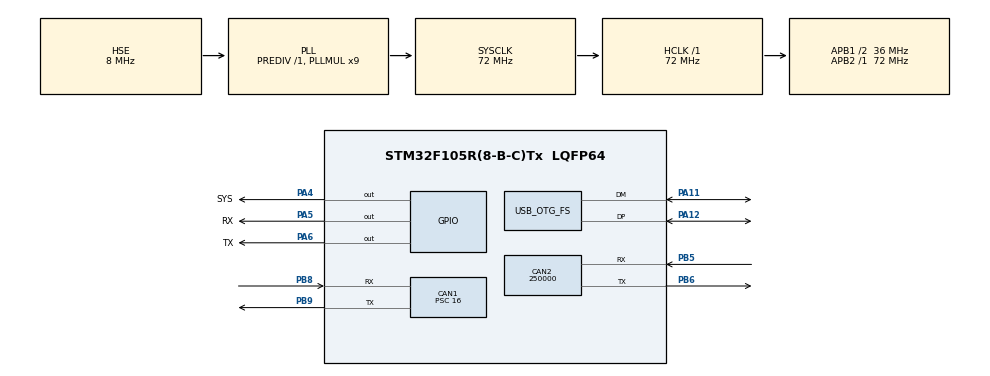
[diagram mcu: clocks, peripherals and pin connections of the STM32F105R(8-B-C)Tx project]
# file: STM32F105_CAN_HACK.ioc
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CAN1.BS1=CAN_BS1_4TQ
CAN1.BS2=CAN_BS2_4TQ
CAN1.CalculateBaudRate=250000
CAN1.CalculateTimeBit=4000
CAN1.CalculateTimeQuantum=444.44444444444446
CAN1.Prescaler=16
CAN2.BS1=CAN_BS1_4TQ
CAN2.BS2=CAN_BS2_4TQ
CAN2.CalculateBaudRate=250000
CAN2.CalculateTimeBit=4000
CAN2.CalculateTimeQuantum=444.44444444444446
Mcu.Family=STM32F1
Mcu.Name=STM32F105R(8-B-C)Tx
Mcu.Package=LQFP64
NVIC.OTG_FS_IRQn=true\:0\:0\:false\:false\:true\:false\:true\:true
NVIC.PriorityGroup=NVIC_PRIORITYGROUP_4
PA11.Mode=Device_Only
PA11.Signal=USB_OTG_FS_DM
PA12.Mode=Device_Only
PA12.Signal=USB_OTG_FS_DP
PA13.Mode=Serial_Wire
PA13.Signal=SYS_JTMS-SWDIO
PA14.Mode=Serial_Wire
PA14.Signal=SYS_JTCK-SWCLK
PA4.GPIO_Label=SYS
PA4.Signal=GPIO_Output
PA5.GPIO_Label=RX
PA5.Signal=GPIO_Output
PA6.GPIO_Label=TX
PA6.Signal=GPIO_Output
PB5.Mode=CAN_Activate
PB5.Signal=CAN2_RX
PB6.Mode=CAN_Activate
PB6.Signal=CAN2_TX
PB8.Mode=CAN_Activate
PB8.Signal=CAN1_RX
PB9.Mode=CAN_Activate
PB9.Signal=CAN1_TX
PD0-OSC_IN.Mode=HSE-External-Oscillator
PD0-OSC_IN.Signal=RCC_OSC_IN
PD1-OSC_OUT.Mode=HSE-External-Oscillator
PD1-OSC_OUT.Signal=RCC_OSC_OUT
ProjectManager.HeapSize=0x200
ProjectManager.StackSize=0x400
ProjectManager.TargetToolchain=STM32CubeIDE
RCC.AHBFreq_Value=72000000
RCC.APB1CLKDivider=RCC_HCLK_DIV2
RCC.APB1Freq_Value=36000000
RCC.APB1TimFreq_Value=72000000
RCC.APB2Freq_Value=72000000
RCC.APB2TimFreq_Value=72000000
RCC.HCLKFreq_Value=72000000
RCC.PLLMUL=RCC_PLL_MUL9
RCC.SYSCLKFreq_VALUE=72000000
RCC.SYSCLKSource=RCC_SYSCLKSOURCE_PLLCLK
RCC.USBFreq_Value=48000000
TIM5.Period=999
TIM5.Prescaler=71
USB_DEVICE.CLASS_NAME_FS=CDC
USB_DEVICE.VirtualMode=Cdc
USB_DEVICE.VirtualModeFS=Cdc_FS
USB_OTG_FS.VirtualMode=Device_Only
VP_TIM5_VS_ClockSourceINT.Mode=Internal
VP_USB_DEVICE_VS_USB_DEVICE_CDC_FS.Mode=CDC_FS
board=custom

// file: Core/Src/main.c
/* USER CODE BEGIN Header */
/**
  ******************************************************************************
  * @file           : main.c
  * @brief          : Main program body
  ******************************************************************************
  * @attention
  *
  * Copyright (c) 2024 STMicroelectronics.
  * All rights reserved.
  *
  * This software is licensed under terms that can be found in the LICENSE file
  * in the root directory of this software component.
  * If no LICENSE file comes with this software, it is provided AS-IS.
  *
  ******************************************************************************
  */
/* USER CODE END Header */
#include "main.h"
#include "usb_device.h"

CAN_HandleTypeDef hcan1;
CAN_HandleTypeDef hcan2;

TIM_HandleTypeDef htim5;

void SystemClock_Config(void);
static void MX_GPIO_Init(void);
static void MX_CAN1_Init(void);
static void MX_CAN2_Init(void);
static void MX_TIM5_Init(void);

/* USER CODE BEGIN 0 */
// Função para ajustar o brilho do LED
/* USER CODE END 0 */

void PulseLEDBrightness(uint32_t interval) {
    static int direction = 1;  // 1 para aumentar brilho, -1 para diminuir
    static uint8_t brightness = 0;  // Começa no brilho mínimo
    static uint32_t cont = 0;  // Contador para controlar a pulsação

    // Aumenta o contador a cada ciclo
    cont++;

    // A cada `interval` ciclos, ajusta o brilho
    if (cont >= interval) {
        cont = 0;  // Reset do contador

        // Ajuste o valor de `brightness` de 0 a 255 para criar o efeito de pulsação
        if (direction == 1) {
            brightness++;  // Aumenta o brilho
            if (brightness >= 255) {
                direction = -1;  // Quando atingir o brilho máximo, inverte a direção
            }
        } else {
            brightness--;  // Diminui o brilho
            if (brightness <= 0) {
                direction = 1;  // Quando atingir o brilho mínimo, inverte a direção
            }
        }

        // Aplica o brilho no LED
        for (int i = 0; i < 255; i++) {
            if (i < brightness) {
                HAL_GPIO_WritePin(GPIOA, SYS_Pin, GPIO_PIN_SET);  // Liga o LED
            } else {
                HAL_GPIO_WritePin(GPIOA, SYS_Pin, GPIO_PIN_RESET);  // Desliga o LED
            }
        }
    }
}

int main(void)
{

  /* MCU Configuration--------------------------------------------------------*/

  /* Reset of all peripherals, Initializes the Flash interface and the Systick. */
  HAL_Init();

  /* Configure the system clock */
  SystemClock_Config();

  /* Initialize all configured peripherals */
  MX_GPIO_Init();
  MX_CAN1_Init();
  MX_CAN2_Init();
  MX_TIM5_Init();
  HAL_Delay(1000);
  MX_USB_DEVICE_Init();
  HAL_TIM_Base_Start(&htim5);  // Inicia o timer para contar de 0 até 0xFFFF
  /* USER CODE BEGIN 2 */
  CAN_Init();
  HAL_GPIO_WritePin(GPIOA, SYS_Pin, GPIO_PIN_SET);
  /* USER CODE END 2 */

  /* Infinite loop */
  while (1)
  {
    CAN_Run();
    //PulseLEDBrightness(200);
  }
}

void SystemClock_Config(void)
{
  RCC_OscInitTypeDef RCC_OscInitStruct = {0};
  RCC_ClkInitTypeDef RCC_ClkInitStruct = {0};
  RCC_PeriphCLKInitTypeDef PeriphClkInit = {0};

  /** Initializes the RCC Oscillators according to the specified parameters
  * in the RCC_OscInitTypeDef structure.
  */
  RCC_OscInitStruct.OscillatorType = RCC_OSCILLATORTYPE_HSE;
  RCC_OscInitStruct.HSEState = RCC_HSE_ON;
  RCC_OscInitStruct.HSEPredivValue = RCC_HSE_PREDIV_DIV1;
  RCC_OscInitStruct.HSIState = RCC_HSI_ON;
  RCC_OscInitStruct.Prediv1Source = RCC_PREDIV1_SOURCE_HSE;
  RCC_OscInitStruct.PLL.PLLState = RCC_PLL_ON;
  RCC_OscInitStruct.PLL.PLLSource = RCC_PLLSOURCE_HSE;
  RCC_OscInitStruct.PLL.PLLMUL = RCC_PLL_MUL9;
  RCC_OscInitStruct.PLL2.PLL2State = RCC_PLL_NONE;
  if (HAL_RCC_OscConfig(&RCC_OscInitStruct) != HAL_OK)
  {
    Error_Handler();
  }

  /** Initializes the CPU, AHB and APB buses clocks
  */
  RCC_ClkInitStruct.ClockType = RCC_CLOCKTYPE_HCLK|RCC_CLOCKTYPE_SYSCLK
                              |RCC_CLOCKTYPE_PCLK1|RCC_CLOCKTYPE_PCLK2;
  RCC_ClkInitStruct.SYSCLKSource = RCC_SYSCLKSOURCE_PLLCLK;
  RCC_ClkInitStruct.AHBCLKDivider = RCC_SYSCLK_DIV1;
  RCC_ClkInitStruct.APB1CLKDivider = RCC_HCLK_DIV2;
  RCC_ClkInitStruct.APB2CLKDivider = RCC_HCLK_DIV1;

  if (HAL_RCC_ClockConfig(&RCC_ClkInitStruct, FLASH_LATENCY_2) != HAL_OK)
  {
    Error_Handler();
  }
  PeriphClkInit.PeriphClockSelection = RCC_PERIPHCLK_USB;
  PeriphClkInit.UsbClockSelection = RCC_USBCLKSOURCE_PLL_DIV3;
  if (HAL_RCCEx_PeriphCLKConfig(&PeriphClkInit) != HAL_OK)
  {
    Error_Handler();
  }

  /** Configure the Systick interrupt time
  */
  __HAL_RCC_PLLI2S_ENABLE();
}

static void MX_CAN1_Init(void)
{

  hcan1.Instance = CAN1;
  hcan1.Init.Prescaler = 16;
  hcan1.Init.Mode = CAN_MODE_NORMAL;
  hcan1.Init.SyncJumpWidth = CAN_SJW_1TQ;
  hcan1.Init.TimeSeg1 = CAN_BS1_4TQ;
  hcan1.Init.TimeSeg2 = CAN_BS2_4TQ;
  hcan1.Init.TimeTriggeredMode = DISABLE;
  hcan1.Init.AutoBusOff = DISABLE;
  hcan1.Init.AutoWakeUp = DISABLE;
  hcan1.Init.AutoRetransmission = DISABLE;
  hcan1.Init.ReceiveFifoLocked = DISABLE;
  hcan1.Init.TransmitFifoPriority = DISABLE;
  if (HAL_CAN_Init(&hcan1) != HAL_OK)
  {
    Error_Handler();
  }

}

static void MX_CAN2_Init(void)
{

  hcan2.Instance = CAN2;
  hcan2.Init.Prescaler = 16;
  hcan2.Init.Mode = CAN_MODE_NORMAL;
  hcan2.Init.SyncJumpWidth = CAN_SJW_1TQ;
  hcan2.Init.TimeSeg1 = CAN_BS1_4TQ;
  hcan2.Init.TimeSeg2 = CAN_BS2_4TQ;
  hcan2.Init.TimeTriggeredMode = DISABLE;
  hcan2.Init.AutoBusOff = DISABLE;
  hcan2.Init.AutoWakeUp = DISABLE;
  hcan2.Init.AutoRetransmission = DISABLE;
  hcan2.Init.ReceiveFifoLocked = DISABLE;
  hcan2.Init.TransmitFifoPriority = DISABLE;
  if (HAL_CAN_Init(&hcan2) != HAL_OK)
  {
    Error_Handler();
  }

}

static void MX_TIM5_Init(void)
{

  TIM_ClockConfigTypeDef sClockSourceConfig = {0};
  TIM_MasterConfigTypeDef sMasterConfig = {0};

  htim5.Instance = TIM5;
  //Ainda precisa ser ajustado para sincronizar o periodo das mensagens.
  htim5.Init.Prescaler = 71999 / 1.13;
  htim5.Init.CounterMode = TIM_COUNTERMODE_UP;
  htim5.Init.Period = 0xFFFF;
  htim5.Init.ClockDivision = TIM_CLOCKDIVISION_DIV1;
  htim5.Init.AutoReloadPreload = TIM_AUTORELOAD_PRELOAD_DISABLE;
  if (HAL_TIM_Base_Init(&htim5) != HAL_OK)
  {
    Error_Handler();
  }
  sClockSourceConfig.ClockSource = TIM_CLOCKSOURCE_INTERNAL;
  if (HAL_TIM_ConfigClockSource(&htim5, &sClockSourceConfig) != HAL_OK)
  {
    Error_Handler();
  }
  sMasterConfig.MasterOutputTrigger = TIM_TRGO_RESET;
  sMasterConfig.MasterSlaveMode = TIM_MASTERSLAVEMODE_DISABLE;
  if (HAL_TIMEx_MasterConfigSynchronization(&htim5, &sMasterConfig) != HAL_OK)
  {
    Error_Handler();
  }

}

static void MX_GPIO_Init(void)
{
  GPIO_InitTypeDef GPIO_InitStruct = {0};

  /* GPIO Ports Clock Enable */
  __HAL_RCC_GPIOD_CLK_ENABLE();
  __HAL_RCC_GPIOA_CLK_ENABLE();
  __HAL_RCC_GPIOB_CLK_ENABLE();

  /*Configure GPIO pin Output Level */
  HAL_GPIO_WritePin(GPIOA, SYS_Pin|RX_Pin|TX_Pin, GPIO_PIN_RESET);

  /*Configure GPIO pins : SYS_Pin RX_Pin TX_Pin */
  GPIO_InitStruct.Pin = SYS_Pin|RX_Pin|TX_Pin;
  GPIO_InitStruct.Mode = GPIO_MODE_OUTPUT_PP;
  GPIO_InitStruct.Pull = GPIO_NOPULL;
  GPIO_InitStruct.Speed = GPIO_SPEED_FREQ_LOW;
  HAL_GPIO_Init(GPIOA, &GPIO_InitStruct);

}

void Error_Handler(void)
{
  __disable_irq();
  while (1)
  {
  }
}
